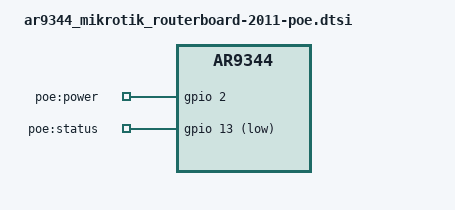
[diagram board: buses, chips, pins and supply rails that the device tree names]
// SPDX-License-Identifier: GPL-2.0-or-later OR MIT

/ {
	gpio-export {
		compatible = "gpio-export";

		gpio_poe_out {
			gpio-export,name = "poe:power";
			gpio-export,output = <0>;
			gpios = <&gpio 2 GPIO_ACTIVE_HIGH>;
		};

		gpio_poe_status {
			gpio-export,name = "poe:status";
			gpios = <&gpio 13 GPIO_ACTIVE_LOW>;
		};
	};
};
